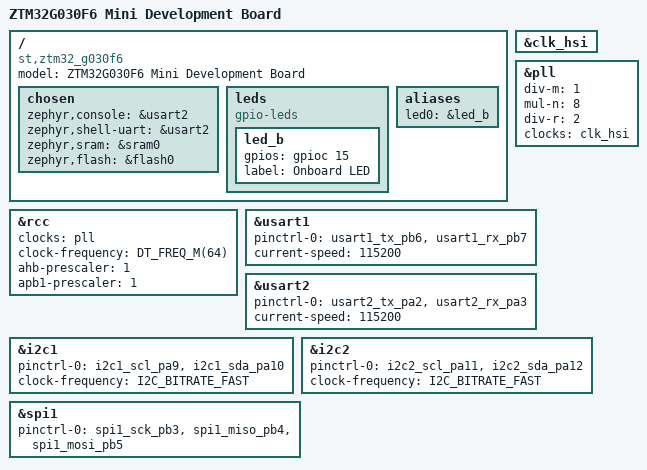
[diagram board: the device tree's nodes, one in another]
/*
 * Copyright (c) 2022 Sullivan Zeng <2257501878@qq.com>
 *
 * SPDX-License-Identifier: Apache-2.0
 */

/dts-v1/;
#include <st/g0/stm32g030X6.dtsi>
#include <st/g0/stm32g030f6px-pinctrl.dtsi>

/ {
	model = "ZTM32G030F6 Mini Development Board";
	compatible = "st,ztm32_g030f6";

	chosen {
		zephyr,console = &usart2;
		zephyr,shell-uart = &usart2;
		zephyr,sram = &sram0;
		zephyr,flash = &flash0;
	};

	leds {
		compatible = "gpio-leds";
		led_b: led_b {
			gpios = <&gpioc 15 GPIO_ACTIVE_HIGH>;
			label = "Onboard LED";
		};
	};

	aliases {
		led0 = &led_b;
	};
};

&clk_hsi {
	status = "okay";
};

&pll {
	div-m = <1>;
	mul-n = <8>;
	div-r = <2>;
	clocks = <&clk_hsi>;
	status = "okay";
};

&rcc {
	clocks = <&pll>;
	clock-frequency = <DT_FREQ_M(64)>;
	ahb-prescaler = <1>;
	apb1-prescaler = <1>;
};

&usart1 {
	pinctrl-0 = <&usart1_tx_pb6 &usart1_rx_pb7>;
	pinctrl-names = "default";
	current-speed = <115200>;
};

&usart2 {
	pinctrl-0 = <&usart2_tx_pa2 &usart2_rx_pa3>;
	pinctrl-names = "default";
	current-speed = <115200>;
	status = "okay";
};

&i2c1 {
	pinctrl-0 = <&i2c1_scl_pa9 &i2c1_sda_pa10>;
	pinctrl-names = "default";
	clock-frequency = <I2C_BITRATE_FAST>;
	status = "okay";
};

&i2c2 {
	pinctrl-0 = <&i2c2_scl_pa11 &i2c2_sda_pa12>;
	pinctrl-names = "default";
	clock-frequency = <I2C_BITRATE_FAST>;
	status = "okay";
};

&spi1 {
	pinctrl-0 = <&spi1_sck_pb3 &spi1_miso_pb4 &spi1_mosi_pb5>;
	pinctrl-names = "default";
	status = "okay";
};
